AUTOSAR XML (schema 4-2-2)
package /Components
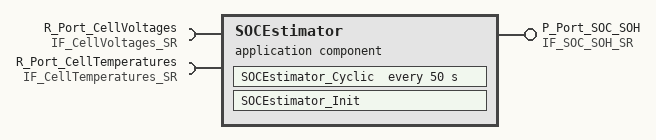
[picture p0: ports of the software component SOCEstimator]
  application sw component type SOCEstimator
    provide port P_Port_SOC_SOH: provided-interface=IF_SOC_SOH_SR
    require port R_Port_CellVoltages: required-interface=IF_CellVoltages_SR
    require port R_Port_CellTemperatures: required-interface=IF_CellTemperatures_SR
    behavior SOCEstimator_InternalBehavior
      init event SOCEstimator_Init_Event: start-on-event=SOCEstimator_Init
      timing event SOCEstimator_50ms_Event: start-on-event=SOCEstimator_Cyclic, period=50
      runnable SOCEstimator_Init
        data-send-points:
          access VA_Init_PackSOC: accessed-variable=P_Port_SOC_SOH.PackSOC
          access VA_Init_PackSOH: accessed-variable=P_Port_SOC_SOH.PackSOH
      runnable SOCEstimator_Cyclic: minimum-start-interval=50
        data-receive-point-by-values:
          4 x access:
            VA_Cyc_CellVoltages_Array: accessed-variable=R_Port_CellVoltages.CellVoltages_Array
            VA_Cyc_PackVoltage: accessed-variable=R_Port_CellVoltages.PackVoltage
            VA_Cyc_CellTemperatures_Array: accessed-variable=R_Port_CellTemperatures.CellTemperatures_Array
            VA_Cyc_PackTemperature: accessed-variable=R_Port_CellTemperatures.PackTemperature
        data-send-points:
          access VA_Cyc_PackSOC: accessed-variable=P_Port_SOC_SOH.PackSOC
          access VA_Cyc_PackSOH: accessed-variable=P_Port_SOC_SOH.PackSOH
